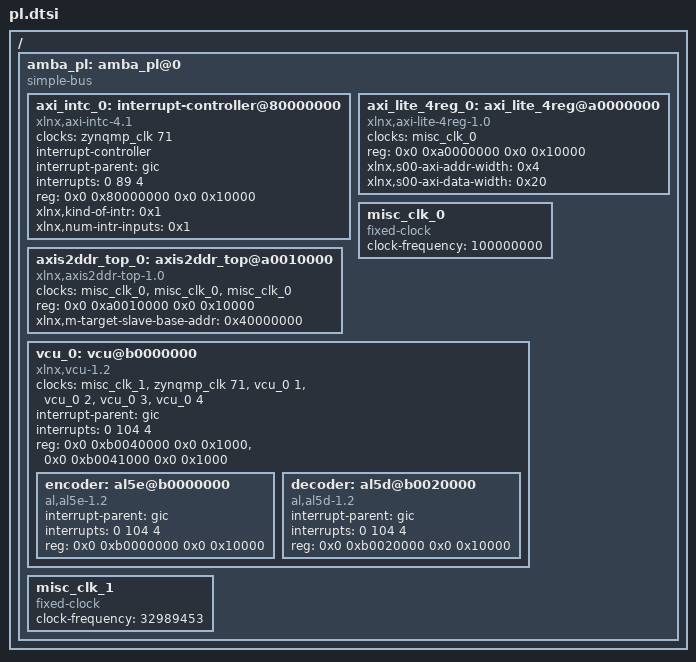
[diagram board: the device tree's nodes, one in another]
/*
 * CAUTION: This file is automatically generated by Xilinx.
 * Version:  
 * Today is: Fri Jun  7 08:23:12 2024
 */


/ {
	amba_pl: amba_pl@0 {
		#address-cells = <2>;
		#size-cells = <2>;
		compatible = "simple-bus";
		ranges ;
		axi_intc_0: interrupt-controller@80000000 {
			#interrupt-cells = <2>;
			clock-names = "s_axi_aclk";
			clocks = <&zynqmp_clk 71>;
			compatible = "xlnx,axi-intc-4.1", "xlnx,xps-intc-1.00.a";
			interrupt-controller ;
			interrupt-names = "irq";
			interrupt-parent = <&gic>;
			interrupts = <0 89 4>;
			reg = <0x0 0x80000000 0x0 0x10000>;
			xlnx,kind-of-intr = <0x1>;
			xlnx,num-intr-inputs = <0x1>;
		};
		axi_lite_4reg_0: axi_lite_4reg@a0000000 {
			clock-names = "s00_axi_aclk";
			clocks = <&misc_clk_0>;
			compatible = "xlnx,axi-lite-4reg-1.0";
			reg = <0x0 0xa0000000 0x0 0x10000>;
			xlnx,s00-axi-addr-width = <0x4>;
			xlnx,s00-axi-data-width = <0x20>;
		};
		misc_clk_0: misc_clk_0 {
			#clock-cells = <0>;
			clock-frequency = <100000000>;
			compatible = "fixed-clock";
		};
		axis2ddr_top_0: axis2ddr_top@a0010000 {
			clock-names = "S_AXIS_ACLK", "S_AXI_ACLK", "M_AXI_ACLK";
			clocks = <&misc_clk_0>, <&misc_clk_0>, <&misc_clk_0>;
			compatible = "xlnx,axis2ddr-top-1.0";
			reg = <0x0 0xa0010000 0x0 0x10000>;
			xlnx,m-target-slave-base-addr = <0x40000000>;
		};
		vcu_0: vcu@b0000000 {
			#address-cells = <2>;
			#clock-cells = <1>;
			#size-cells = <2>;
			clock-names = "pll_ref", "aclk", "vcu_core_enc", "vcu_core_dec", "vcu_mcu_enc", "vcu_mcu_dec";
			clocks = <&misc_clk_1>, <&zynqmp_clk 71>, <&vcu_0 1>, <&vcu_0 2>, <&vcu_0 3>, <&vcu_0 4>;
			compatible = "xlnx,vcu-1.2", "xlnx,vcu";
			interrupt-names = "vcu_host_interrupt";
			interrupt-parent = <&gic>;
			interrupts = <0 104 4>;
			ranges ;
			reg = <0x0 0xb0040000 0x0 0x1000>, <0x0 0xb0041000 0x0 0x1000>;
			reg-names = "vcu_slcr", "logicore";
			encoder: al5e@b0000000 {
				compatible = "al,al5e-1.2", "al,al5e";
				interrupt-parent = <&gic>;
				interrupts = <0 104 4>;
				reg = <0x0 0xb0000000 0x0 0x10000>;
			};
			decoder: al5d@b0020000 {
				compatible = "al,al5d-1.2", "al,al5d";
				interrupt-parent = <&gic>;
				interrupts = <0 104 4>;
				reg = <0x0 0xb0020000 0x0 0x10000>;
			};
		};
		misc_clk_1: misc_clk_1 {
			#clock-cells = <0>;
			clock-frequency = <32989453>;
			compatible = "fixed-clock";
		};
	};
};
